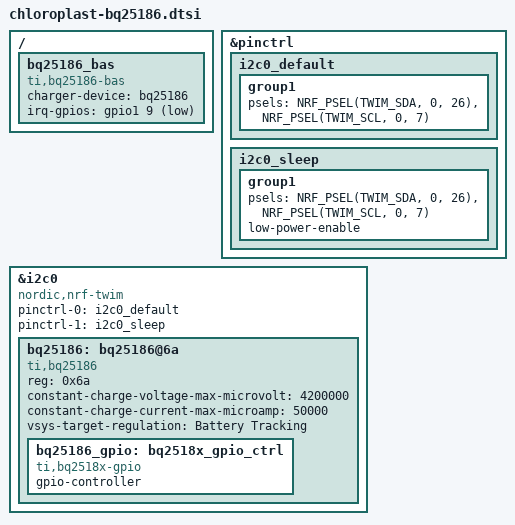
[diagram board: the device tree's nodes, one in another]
/*
 * Copyright (c) 2026 badjeff
 * SPDX-License-Identifier: MIT
 */

&pinctrl {
    i2c0_default: i2c0_default {
        group1 {
            psels = <NRF_PSEL(TWIM_SDA, 0, 26)>,
                    <NRF_PSEL(TWIM_SCL, 0, 7)>;
        };
    };

    i2c0_sleep: i2c0_sleep {
        group1 {
            psels = <NRF_PSEL(TWIM_SDA, 0, 26)>,
                    <NRF_PSEL(TWIM_SCL, 0, 7)>;
            low-power-enable;
        };
    };
};

&i2c0 {
	status = "okay";
	compatible = "nordic,nrf-twim";
	pinctrl-0 = <&i2c0_default>;
	pinctrl-1 = <&i2c0_sleep>;
	pinctrl-names = "default", "sleep";

	bq25186: bq25186@6a {
		compatible = "ti,bq25186";
		reg = <0x6a>;
		status = "okay";
        constant-charge-voltage-max-microvolt = <4200000>; // 4.2V
        constant-charge-current-max-microamp = <50000>; // 50mA
        vsys-target-regulation = "Battery Tracking";

        bq25186_gpio: bq2518x_gpio_ctrl {
            compatible = "ti,bq2518x-gpio";
            gpio-controller;
            #gpio-cells = <2>;
            status = "okay";
        };
	};
};

/{
    bq25186_bas {
        compatible = "ti,bq25186-bas";
        status = "okay";
        charger-device = <&bq25186>;
        irq-gpios = <&gpio1 9 (GPIO_ACTIVE_LOW | GPIO_PULL_UP)>;
    };
};
